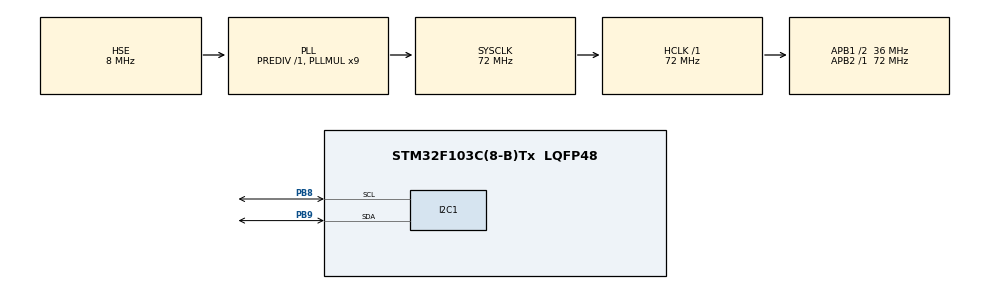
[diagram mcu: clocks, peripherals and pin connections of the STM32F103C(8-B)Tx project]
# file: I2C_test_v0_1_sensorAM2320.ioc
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Mcu.Family=STM32F1
RCC.PLLSourceVirtual=RCC_PLLSOURCE_HSE
PD1-OSC_OUT.Mode=HSE-External-Oscillator
PD0-OSC_IN.Signal=RCC_OSC_IN
RCC.APB1CLKDivider=RCC_HCLK_DIV2
VP_SYS_VS_ND.Mode=No_Debug
RCC.SYSCLKSource=RCC_SYSCLKSOURCE_PLLCLK
ProjectManager.StackSize=0x400
PD1-OSC_OUT.Signal=RCC_OSC_OUT
ProjectManager.TargetToolchain=STM32CubeIDE
RCC.HCLKFreq_Value=72000000
PB9.Mode=I2C
RCC.APB2TimFreq_Value=72000000
RCC.USBFreq_Value=72000000
RCC.AHBFreq_Value=72000000
PD0-OSC_IN.Mode=HSE-External-Oscillator
board=custom
RCC.PLLMUL=RCC_PLL_MUL9
RCC.APB2Freq_Value=72000000
Mcu.Name=STM32F103C(8-B)Tx
RCC.SYSCLKFreq_VALUE=72000000
PB9.Signal=I2C1_SDA
Mcu.Package=LQFP48
ProjectManager.HeapSize=0x200
NVIC.PriorityGroup=NVIC_PRIORITYGROUP_4
PB8.Mode=I2C
RCC.APB1TimFreq_Value=72000000
PB8.Signal=I2C1_SCL
RCC.APB1Freq_Value=36000000

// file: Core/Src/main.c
/* USER CODE BEGIN Header */
/**
  ******************************************************************************
  * @file           : main.c
  * @brief          : Main program body
  ******************************************************************************
  * @attention
  *
  * <h2><center>&copy; Copyright (c) 2021 STMicroelectronics.
  * All rights reserved.</center></h2>
  *
  * This software component is licensed by ST under BSD 3-Clause license,
  * the "License"; You may not use this file except in compliance with the
  * License. You may obtain a copy of the License at:
  *                        opensource.org/licenses/BSD-3-Clause
  *
  ******************************************************************************
  */
/* USER CODE END Header */
#include "main.h"

/* USER CODE BEGIN Includes */
/* USER CODE BEGIN Includes */
#include "i2c-lcd.h"
#include "stdio.h"
#include "am2320.h"
/* USER CODE END Includes */

I2C_HandleTypeDef hi2c1;

void SystemClock_Config(void);
static void MX_GPIO_Init(void);
static void MX_I2C1_Init(void);
/* USER CODE BEGIN PFP */
void testa_display(void);
/* USER CODE END PFP */

int main(void)
{
  /* USER CODE BEGIN 1 */
  char buf[5];
  /* USER CODE END 1 */

  /* MCU Configuration--------------------------------------------------------*/

  /* Reset of all peripherals, Initializes the Flash interface and the Systick. */
  HAL_Init();

  /* Configure the system clock */
  SystemClock_Config();

  /* Initialize all configured peripherals */
  MX_GPIO_Init();
  MX_I2C1_Init();
  /* USER CODE BEGIN 2 */

  lcd_init();

  Am2320_HandleTypeDef Am2320_;
  Am2320_ = am2320_Init(&hi2c1, AM2320_ADDRESS);
  float temperature, humidity;

  testa_display();
  lcd_clear();
  lcd_posiciona(0, 0);
  lcd_send_string ("Sist.  inicializado!");
  HAL_Delay (1000);  // wait for 1 sec

  lcd_clear();
  lcd_posiciona(3, 4);
  lcd_send_string ("A.C.T.  2021");
  /* USER CODE END 2 */

  /* Infinite loop */
  while (1)
  {
	am2320_GetTemperatureAndHumidity(&Am2320_, &temperature, &humidity);

	lcd_posiciona(0, 0);
	lcd_send_string ("Temp=");
	sprintf (buf, "%.2f", temperature);
	lcd_send_string (buf);
	lcd_send_string (" deg ");

	lcd_posiciona(1, 0);
	lcd_send_string ("Umid=");
	sprintf (buf, "%.2f", humidity);
	lcd_send_string (buf);
	lcd_send_string (" % ");

	HAL_Delay(250);
  }
}

void SystemClock_Config(void)
{
  RCC_OscInitTypeDef RCC_OscInitStruct = {0};
  RCC_ClkInitTypeDef RCC_ClkInitStruct = {0};

  /** Initializes the RCC Oscillators according to the specified parameters
  * in the RCC_OscInitTypeDef structure.
  */
  RCC_OscInitStruct.OscillatorType = RCC_OSCILLATORTYPE_HSE;
  RCC_OscInitStruct.HSEState = RCC_HSE_ON;
  RCC_OscInitStruct.HSEPredivValue = RCC_HSE_PREDIV_DIV1;
  RCC_OscInitStruct.HSIState = RCC_HSI_ON;
  RCC_OscInitStruct.PLL.PLLState = RCC_PLL_ON;
  RCC_OscInitStruct.PLL.PLLSource = RCC_PLLSOURCE_HSE;
  RCC_OscInitStruct.PLL.PLLMUL = RCC_PLL_MUL9;
  if (HAL_RCC_OscConfig(&RCC_OscInitStruct) != HAL_OK)
  {
    Error_Handler();
  }
  /** Initializes the CPU, AHB and APB buses clocks
  */
  RCC_ClkInitStruct.ClockType = RCC_CLOCKTYPE_HCLK|RCC_CLOCKTYPE_SYSCLK
                              |RCC_CLOCKTYPE_PCLK1|RCC_CLOCKTYPE_PCLK2;
  RCC_ClkInitStruct.SYSCLKSource = RCC_SYSCLKSOURCE_PLLCLK;
  RCC_ClkInitStruct.AHBCLKDivider = RCC_SYSCLK_DIV1;
  RCC_ClkInitStruct.APB1CLKDivider = RCC_HCLK_DIV2;
  RCC_ClkInitStruct.APB2CLKDivider = RCC_HCLK_DIV1;

  if (HAL_RCC_ClockConfig(&RCC_ClkInitStruct, FLASH_LATENCY_2) != HAL_OK)
  {
    Error_Handler();
  }
}

static void MX_I2C1_Init(void)
{

  hi2c1.Instance = I2C1;
  hi2c1.Init.ClockSpeed = 100000;
  hi2c1.Init.DutyCycle = I2C_DUTYCYCLE_2;
  hi2c1.Init.OwnAddress1 = 0;
  hi2c1.Init.AddressingMode = I2C_ADDRESSINGMODE_7BIT;
  hi2c1.Init.DualAddressMode = I2C_DUALADDRESS_DISABLE;
  hi2c1.Init.OwnAddress2 = 0;
  hi2c1.Init.GeneralCallMode = I2C_GENERALCALL_DISABLE;
  hi2c1.Init.NoStretchMode = I2C_NOSTRETCH_DISABLE;
  if (HAL_I2C_Init(&hi2c1) != HAL_OK)
  {
    Error_Handler();
  }

}

static void MX_GPIO_Init(void)
{

  /* GPIO Ports Clock Enable */
  __HAL_RCC_GPIOD_CLK_ENABLE();
  __HAL_RCC_GPIOB_CLK_ENABLE();

}

/* USER CODE BEGIN 4 */
void testa_display(void)
{
	int i=0, j=0;
	int col=0, row=0;

	lcd_clear();
	lcd_posiciona(3, 0);
	lcd_send_string ("      ACT  2021     ");
	lcd_posiciona(0, 2);
	lcd_send_string ("LCD DRIVER TEST  ");

	HAL_Delay (500);  // espera 1 segundo / 1000ms

	lcd_clear();
	for (i=0;i<256;i++)
	{
		j=i%80;
		col=j%20;
		row=j/20;
		lcd_posiciona(row, col);
		lcd_send_data(i+48);

		HAL_Delay(25);
	}
}
/* USER CODE END 4 */

void Error_Handler(void)
{
  __disable_irq();
  while (1)
  {
  }
}

/************************ (C) COPYRIGHT STMicroelectronics *****END OF FILE****/
